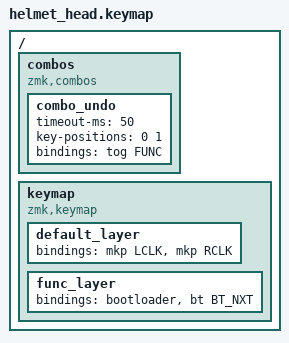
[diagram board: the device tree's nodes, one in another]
/*
 * Copyright (c) 2020 The ZMK Contributors
 *
 * SPDX-License-Identifier: MIT
 */

#include <behaviors.dtsi>
#include <dt-bindings/zmk/keys.h>
#include <dt-bindings/zmk/bt.h>
#include <dt-bindings/zmk/mouse.h>
#include <behaviors/mouse_keys.dtsi>

#define DEFAULT 0
#define FUNC    1

/ {
    combos {
        compatible = "zmk,combos";
        combo_undo {
            timeout-ms = <50>;
            key-positions = <0 1>;
            bindings = <&tog FUNC>;
        };
    };
};

/ {
    keymap {
        compatible = "zmk,keymap";

        default_layer {
            bindings = <
                &mkp LCLK
                &mkp RCLK
            >;
        };

        func_layer {
            bindings = <
                &bootloader
                &bt BT_NXT
            >;
        };
    };
};
